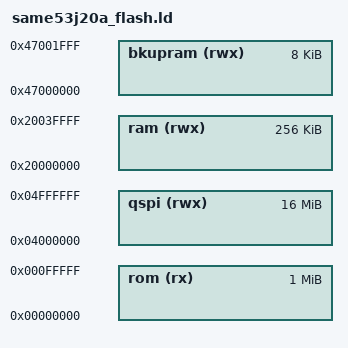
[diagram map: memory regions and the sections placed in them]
/**
 * \file
 *
 * \brief Linker script for running in internal FLASH on the SAME53J20A
 *
 * Copyright (c) 2018 Microchip Technology Inc.
 *
 * \asf_license_start
 *
 * \page License
 *
 * SPDX-License-Identifier: Apache-2.0
 *
 * Licensed under the Apache License, Version 2.0 (the "License"); you may
 * not use this file except in compliance with the License.
 * You may obtain a copy of the Licence at
 * 
 * http://www.apache.org/licenses/LICENSE-2.0
 * 
 * Unless required by applicable law or agreed to in writing, software
 * distributed under the License is distributed on an AS IS BASIS, WITHOUT
 * WARRANTIES OR CONDITIONS OF ANY KIND, either express or implied.
 * See the License for the specific language governing permissions and
 * limitations under the License.
 *
 * \asf_license_stop
 *
 */


OUTPUT_FORMAT("elf32-littlearm", "elf32-littlearm", "elf32-littlearm")
OUTPUT_ARCH(arm)
SEARCH_DIR(.)

/* Memory Spaces Definitions */
MEMORY
{
  rom      (rx)  : ORIGIN = 0x00000000, LENGTH = 0x00100000
  ram      (rwx) : ORIGIN = 0x20000000, LENGTH = 0x00040000
  bkupram  (rwx) : ORIGIN = 0x47000000, LENGTH = 0x00002000
  qspi     (rwx) : ORIGIN = 0x04000000, LENGTH = 0x01000000
}

/* The stack size used by the application. NOTE: you need to adjust according to your application. */
STACK_SIZE = DEFINED(STACK_SIZE) ? STACK_SIZE : DEFINED(__stack_size__) ? __stack_size__ : 0x10000;

INCLUDE same53_flash.ld
